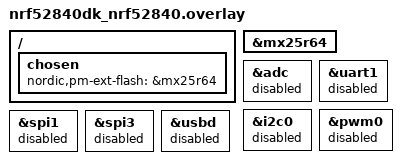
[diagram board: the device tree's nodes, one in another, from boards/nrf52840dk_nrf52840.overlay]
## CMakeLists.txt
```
#
# Copyright (c) 2021 Nordic Semiconductor ASA
#
# SPDX-License-Identifier: LicenseRef-Nordic-5-Clause
#

cmake_minimum_required(VERSION 3.20.0)

include(${CMAKE_CURRENT_LIST_DIR}/../../cmake/find_zephyr.cmake)

project(matter-light-switch)

# NORDIC SDK APP START

# Include all source files that are located in the Matter common directory.
include(${ZEPHYR_NCS_MATTER_MODULE_DIR}/cmake/sample.cmake)

ncs_get_zap_parent_dir(ZAP_PARENT_DIR)

target_include_directories(app PRIVATE
  src
  ${ZAP_PARENT_DIR}
)

target_compile_options(app PRIVATE -Wno-deprecated-declarations)

target_sources(app PRIVATE
  src/app_task.cpp
  src/light_switch.cpp
  src/main.cpp
  src/shell_commands.cpp
  ${ZEPHYR_NCS_MATTER_MODULE_DIR}/subsys/binding/binding_handler.cpp
)

ncs_configure_data_model()
# NORDIC SDK APP END
```

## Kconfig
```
#
# Copyright (c) 2022 Nordic Semiconductor
#
# SPDX-License-Identifier: LicenseRef-Nordic-5-Clause
#
mainmenu "Matter nRF Connect Light Switch Example Application"

config STATE_LEDS
	bool "Use LEDs to indicate the device state"
	default y
	help
	  Use LEDs to render the current state of the device such as the progress of commissioning of
	  the device into a network or the factory reset initiation. Note that setting this option to
	  'n' does not disable the LED indicating the state of the simulated bolt.

# Sample configuration used for Thread networking
if OPENTHREAD

choice OPENTHREAD_NORDIC_LIBRARY_CONFIGURATION
	default OPENTHREAD_NORDIC_LIBRARY_MTD
endchoice

choice OPENTHREAD_DEVICE_TYPE
	default OPENTHREAD_MTD
endchoice

choice OPENTHREAD_IMPLEMENTATION
	default OPENTHREAD_SOURCES
endchoice

config CHIP_ENABLE_ICD_SUPPORT
	default y

# Reduce Thread TX output power to 0 dBm for SED device
config OPENTHREAD_DEFAULT_TX_POWER
	default 0

endif # OPENTHREAD

if SHIELD_NRF7002EB2

config CHIP_WIFI
	default y

config NRF_WIFI_LOW_POWER
	default y

endif # SHIELD_NRF7002EB2

# Enable Read Client functionality for all build configurations.
config CHIP_ENABLE_READ_CLIENT
	default y

source "$(ZEPHYR_CONNECTEDHOMEIP_MODULE_DIR)/config/nrfconnect/chip-module/Kconfig.features"
source "$(ZEPHYR_CONNECTEDHOMEIP_MODULE_DIR)/config/nrfconnect/chip-module/Kconfig.defaults"
source "Kconfig.zephyr"
```

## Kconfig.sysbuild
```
#
# Copyright (c) 2023 Nordic Semiconductor ASA
#
# SPDX-License-Identifier: LicenseRef-Nordic-5-Clause
#

config MATTER_ADD_ON
	default y

#### Radio core selection
config NRF_DEFAULT_IPC_RADIO
	default y

# Enable IEEE802.15.4 serialization to network core
# This config automatically pulls in the `overlay-802154.conf` in the ipc_radio image
config NETCORE_IPC_RADIO_IEEE802154
	default y if SOC_SERIES_NRF53 && !WIFI_NRF70

# Enable Bluetooth serialization to network core
# This config automatically pulls in the `overlay-bt_hci_ipc.conf` in the ipc_radio image
config NETCORE_IPC_RADIO_BT_HCI_IPC
	default y if SOC_SERIES_NRF53

#### Matter OTA
config MATTER_ADD_ON_OTA
	default n if BOARD_NRF7120DK_NRF7120_CPUAPP

#### Bootloader
choice BOOTLOADER
	default BOOTLOADER_MCUBOOT if !BOARD_NRF21540DK && !BOARD_NRF7120DK_NRF7120_CPUAPP
endchoice

if BOOTLOADER_MCUBOOT

#### DFU multi-image support
config DFU_MULTI_IMAGE_PACKAGE_BUILD
	default y

config DFU_MULTI_IMAGE_PACKAGE_APP
	default y

#### DFU network core configuration
if SOC_SERIES_NRF53

choice MCUBOOT_MODE
	default MCUBOOT_MODE_OVERWRITE_ONLY
endchoice

choice BOOT_SIGNATURE_TYPE
	default BOOT_SIGNATURE_TYPE_RSA
endchoice

config SECURE_BOOT_NETCORE
	default y

config NETCORE_APP_UPDATE
	default y

config DFU_MULTI_IMAGE_PACKAGE_NET
	default y

endif # SOC_SERIES_NRF53
endif # BOOTLOADER_MCUBOOT

#### Enable generating factory data
config MATTER_ADD_ON_FACTORY_DATA_GENERATE
	default y if !BOARD_NRF21540DK

source "share/sysbuild/Kconfig"
```

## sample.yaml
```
sample:
  description: Matter Light Switch example
  name: Matter Light Switch
common:
  tags:
    - sysbuild
    - ci_samples_matter
tests:
  sample.matter.light_switch.debug:
    sysbuild: true
    build_only: true
    integration_platforms:
      - nrf5340dk/nrf5340/cpuapp
      - nrf54lm20dk/nrf54lm20b/cpuapp
      - nrf54lm20dk/nrf54lm20a/cpuapp
    platform_allow:
      - nrf5340dk/nrf5340/cpuapp
      - nrf54l15dk/nrf54l15/cpuapp
      - nrf54lm20dk/nrf54lm20b/cpuapp
      - nrf54lm20dk/nrf54lm20a/cpuapp
  sample.matter.light_switch.nrf7002eb2.debug:
    sysbuild: true
    build_only: true
    extra_args:
      - light_switch_SHIELD=nrf7002eb2
      - SB_CONFIG_WIFI_NRF70=y
    integration_platforms:
      - nrf54lm20dk/nrf54lm20b/cpuapp
      - nrf54lm20dk/nrf54lm20a/cpuapp
    platform_allow:
      - nrf54lm20dk/nrf54lm20b/cpuapp
      - nrf54lm20dk/nrf54lm20a/cpuapp
  sample.matter.light_switch.nrf7120.debug:
    sysbuild: true
    build_only: true
    extra_args:
      - CONFIG_CHIP_WIFI=y
      - CONFIG_WIFI_NRF71_PATCH=y
      - EXTRA_DTC_OVERLAY_FILE=${ZEPHYR_NRFXLIB_MODULE_DIR}/nrf71_wifi/bins/0.1.0/nrf7120_wifi_patch.dtsi
    integration_platforms:
      - nrf7120dk/nrf7120/cpuapp
    platform_allow:
      - nrf7120dk/nrf7120/cpuapp
  sample.matter.light_switch.release:
    sysbuild: true
    build_only: true
    extra_args:
      - FILE_SUFFIX=release
    integration_platforms:
      - nrf54lm20dk/nrf54lm20b/cpuapp
      - nrf54lm20dk/nrf54lm20a/cpuapp
    platform_allow:
      - nrf5340dk/nrf5340/cpuapp
      - nrf54l15dk/nrf54l15/cpuapp
      - nrf54lm20dk/nrf54lm20b/cpuapp
      - nrf54lm20dk/nrf54lm20a/cpuapp
  sample.matter.light_switch.nrf7002eb2.release:
    sysbuild: true
    build_only: true
    extra_args:
      - FILE_SUFFIX=release
      - light_switch_SHIELD=nrf7002eb2
      - SB_CONFIG_WIFI_NRF70=y
    integration_platforms:
      - nrf54lm20dk/nrf54lm20b/cpuapp
      - nrf54lm20dk/nrf54lm20a/cpuapp
    platform_allow:
      - nrf54lm20dk/nrf54lm20b/cpuapp
      - nrf54lm20dk/nrf54lm20a/cpuapp
  sample.matter.light_switch.nrf7120.release:
    sysbuild: true
    build_only: true
    extra_args:
      - FILE_SUFFIX=release
      - CONFIG_CHIP_WIFI=y
      - CONFIG_WIFI_NRF71_PATCH=y
      - EXTRA_DTC_OVERLAY_FILE=${ZEPHYR_NRFXLIB_MODULE_DIR}/nrf71_wifi/bins/0.1.0/nrf7120_wifi_patch.dtsi
    integration_platforms:
      - nrf7120dk/nrf7120/cpuapp
    platform_allow:
      - nrf7120dk/nrf7120/cpuapp
  sample.matter.light_switch.lit_icd:
    sysbuild: true
    build_only: true
    extra_args:
      - EXTRA_CONF_FILE=icd_lit.conf
    integration_platforms:
      - nrf5340dk/nrf5340/cpuapp
      - nrf54l15dk/nrf54l15/cpuapp
    platform_allow:
      - nrf5340dk/nrf5340/cpuapp
      - nrf54l15dk/nrf54l15/cpuapp
  sample.matter.light_switch.tfm:
    sysbuild: true
    build_only: true
    extra_args:
      - FILE_SUFFIX=tfm
    integration_platforms:
      - nrf54l15dk/nrf54l15/cpuapp/ns
    platform_allow:
      - nrf54l15dk/nrf54l15/cpuapp/ns
```

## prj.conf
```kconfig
#
# Copyright (c) 2021 Nordic Semiconductor ASA
#
# SPDX-License-Identifier: LicenseRef-Nordic-5-Clause
#

# Enable CHIP
CONFIG_CHIP=y
CONFIG_CHIP_PROJECT_CONFIG="src/chip_project_config.h"
CONFIG_CHIP_DEVICE_PRODUCT_NAME="Matter Light Switch"

# Configure ZAP file name
CONFIG_MATTER_ZAP_FILE_PATH="${APPLICATION_CONFIG_DIR}/src/default_zap/light_switch.zap"

# 32772 == 0x8004 (example light-switch-app)
CONFIG_CHIP_DEVICE_PRODUCT_ID=32772
CONFIG_STD_CPP17=y

# Enable Matter pairing automatically on application start.
CONFIG_CHIP_ENABLE_PAIRING_AUTOSTART=y

# Enable Matter extended announcement and increase duration to 1 hour.
CONFIG_CHIP_BLE_EXT_ADVERTISING=y
CONFIG_CHIP_BLE_ADVERTISING_DURATION=60

# Add support for LEDs and buttons on Nordic development kits
CONFIG_DK_LIBRARY=y

# Bluetooth Low Energy configuration
CONFIG_BT_DEVICE_NAME="MatterSwitch"

# Suspend devices when the CPU goes into sleep
CONFIG_PM_DEVICE=y

# Other settings
CONFIG_THREAD_NAME=y
CONFIG_MPU_STACK_GUARD=y
CONFIG_RESET_ON_FATAL_ERROR=n
CONFIG_CHIP_LIB_SHELL=y
CONFIG_MATTER_TEST_SHELL=y

# Reduce application size
CONFIG_USE_SEGGER_RTT=n

# Enable Factory Data feature
CONFIG_CHIP_FACTORY_DATA=y
CONFIG_CHIP_FACTORY_DATA_BUILD=y
```

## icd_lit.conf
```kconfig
#
# Copyright (c) 2026 Nordic Semiconductor ASA
#
# SPDX-License-Identifier: LicenseRef-Nordic-5-Clause
#

# Enable LIT ICD configuration
CONFIG_CHIP_ICD_LIT_SUPPORT=y
CONFIG_CHIP_ICD_SIT_SLOW_POLL_LIMIT=5000
CONFIG_CHIP_ICD_REPORT_ON_ACTIVE_MODE=y

# Configure ZAP file name
CONFIG_MATTER_ZAP_FILE_PATH="${APPLICATION_CONFIG_DIR}/src/lit_icd_zap/light_switch.zap"
```

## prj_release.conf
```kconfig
#
# Copyright (c) 2021 Nordic Semiconductor ASA
#
# SPDX-License-Identifier: LicenseRef-Nordic-5-Clause
#

# Enable CHIP
CONFIG_CHIP=y
CONFIG_CHIP_PROJECT_CONFIG="src/chip_project_config.h"
CONFIG_CHIP_DEVICE_PRODUCT_NAME="Matter Light Switch"

# Configure ZAP file name
CONFIG_MATTER_ZAP_FILE_PATH="${APPLICATION_CONFIG_DIR}/src/default_zap/light_switch.zap"

# 32772 == 0x8004 (example light-switch-app)
CONFIG_CHIP_DEVICE_PRODUCT_ID=32772
CONFIG_STD_CPP17=y

# Enable Matter pairing automatically on application start.
CONFIG_CHIP_ENABLE_PAIRING_AUTOSTART=y

# Enable Matter extended announcement and increase duration to 1 hour.
CONFIG_CHIP_BLE_EXT_ADVERTISING=y
CONFIG_CHIP_BLE_ADVERTISING_DURATION=60

# Add support for LEDs and buttons on Nordic development kits
CONFIG_DK_LIBRARY=y

# Try to disable unused RAM blocks to reduce power consumption
CONFIG_RAM_POWER_DOWN_LIBRARY=y

# Bluetooth Low Energy configuration
CONFIG_BT_DEVICE_NAME="MatterSwitch"

# Suspend devices when the CPU goes into sleep
CONFIG_PM_DEVICE=y

# Enable system reset on fatal error
CONFIG_RESET_ON_FATAL_ERROR=y

# Disable all debug features
CONFIG_USE_SEGGER_RTT=n
CONFIG_SHELL=n
CONFIG_OPENTHREAD_SHELL=n
CONFIG_CONSOLE=n
CONFIG_UART_CONSOLE=n
CONFIG_SERIAL=n
CONFIG_LOG=n
CONFIG_LOG_MODE_MINIMAL=n
CONFIG_ASSERT_VERBOSE=n
CONFIG_ASSERT_NO_FILE_INFO=y
CONFIG_PRINTK=n
CONFIG_PRINTK_SYNC=n
CONFIG_THREAD_NAME=n
CONFIG_BOOT_BANNER=n

# Enable Factory Data feature
CONFIG_CHIP_FACTORY_DATA=y
CONFIG_CHIP_FACTORY_DATA_BUILD=y

# Enable Watchdog
CONFIG_MATTER_WATCHDOG=y

# Enable LTO to decrease the flash usage.
CONFIG_LTO=y
CONFIG_ISR_TABLES_LOCAL_DECLARATION=y
```

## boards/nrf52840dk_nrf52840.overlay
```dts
/*
 * Copyright (c) 2021 Nordic Semiconductor ASA
 *
 * SPDX-License-Identifier: LicenseRef-Nordic-5-Clause
 */

#include <nrf52840_partitions.dtsi>

/ {
	chosen {
		nordic,pm-ext-flash = &mx25r64;
	};
};

&mx25r64 {
	status = "okay";
};

/* Disable unused peripherals to reduce power consumption */
&adc {
	status = "disabled";
};

&uart1 {
	status = "disabled";
};

&i2c0 {
	status = "disabled";
};

&pwm0 {
	status = "disabled";
};

&spi1 {
	status = "disabled";
};

&spi3 {
	status = "disabled";
};

&usbd {
	status = "disabled";
};
```

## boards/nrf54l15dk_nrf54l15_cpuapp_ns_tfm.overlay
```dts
/*
 * Copyright (c) 2026 Nordic Semiconductor ASA
 *
 * SPDX-License-Identifier: LicenseRef-Nordic-5-Clause
 */

#include <nrf54l15_cpuapp_tfm_application_partitions.dtsi>

/ {
	aliases {
		/* Use watchdog wdt31 as the application watchdog */
		watchdog0 = &wdt31;
	};

	chosen {
		nordic,pm-ext-flash = &mx25r64;
	};
};

&mx25r64 {
	status = "okay";
};

&wdt31 {
	status = "okay";
};

/* Change IRQ ids to handle button interrupts.
 * The default values for nRF54L15 are 219 and 269,
 * but with TF-M they are reserved for the secure domain
 * (218 and 268 are reserved for the non-secure domain).
 */
&gpiote20 {
	interrupts = <218 NRF_DEFAULT_IRQ_PRIORITY>;
};

&gpiote30 {
	interrupts = <268 NRF_DEFAULT_IRQ_PRIORITY>;
};
```

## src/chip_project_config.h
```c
/*
 * Copyright (c) 2022 Nordic Semiconductor ASA
 *
 * SPDX-License-Identifier: LicenseRef-Nordic-5-Clause
 */

#pragma once

#include "../../../subsys/app/chip_project_config_native_sim.h"

#define CHIP_CONFIG_CONTROLLER_MAX_ACTIVE_DEVICES 2
```

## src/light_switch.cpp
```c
/*
 * Copyright (c) 2022 Nordic Semiconductor ASA
 *
 * SPDX-License-Identifier: LicenseRef-Nordic-5-Clause
 */

#include "light_switch.h"
#include "binding/binding_handler.h"

#ifdef CONFIG_CHIP_LIB_SHELL
#include "shell_commands.h"
#endif

#include <app/clusters/bindings/binding-table.h>
#include <app/server/Server.h>
#include <controller/InvokeInteraction.h>
#include <platform/CHIPDeviceLayer.h>
#include <zephyr/logging/log.h>

using namespace chip;
using namespace chip::app;
using namespace chip::app::Clusters;

LOG_MODULE_DECLARE(app, CONFIG_CHIP_APP_LOG_LEVEL);

void LightSwitch::Init(chip::EndpointId lightSwitchEndpoint)
{
	Nrf::Matter::BindingHandler::Init();
#ifdef CONFIG_CHIP_LIB_SHELL
	SwitchCommands::RegisterSwitchCommands();
#endif
	mLightSwitchEndpoint = lightSwitchEndpoint;
}

void LightSwitch::InitiateActionSwitch(Action action)
{
	Nrf::Matter::BindingHandler::BindingData *data = Platform::New<Nrf::Matter::BindingHandler::BindingData>();
	if (data) {
		data->EndpointId = mLightSwitchEndpoint;
		data->ClusterId = Clusters::OnOff::Id;
		data->InvokeCommandFunc = SwitchChangedHandler;
		switch (action) {
		case Action::Toggle:
			data->CommandId = Clusters::OnOff::Commands::Toggle::Id;
			break;
		case Action::On:
			data->CommandId = Clusters::OnOff::Commands::On::Id;
			break;
		case Action::Off:
			data->CommandId = Clusters::OnOff::Commands::Off::Id;
			break;
		default:
			Platform::Delete(data);
			return;
		}
		Nrf::Matter::BindingHandler::RunBoundClusterAction(data);
	}
}

void LightSwitch::DimmerChangeBrightness()
{
	static uint16_t sBrightness;
	Nrf::Matter::BindingHandler::BindingData *data = Platform::New<Nrf::Matter::BindingHandler::BindingData>();
	if (data) {
		data->EndpointId = mLightSwitchEndpoint;
		data->CommandId = Clusters::LevelControl::Commands::MoveToLevel::Id;
		data->ClusterId = Clusters::LevelControl::Id;
		data->InvokeCommandFunc = SwitchChangedHandler;
		/* add to brightness 3 to approximate 1% step of brightness after each call dimmer change. */
		sBrightness += kOnePercentBrightnessApproximation;
		if (sBrightness > kMaximumBrightness) {
			sBrightness = 0;
		}
		data->Value = (uint8_t)sBrightness;
		Nrf::Matter::BindingHandler::RunBoundClusterAction(data);
	}
}

void LightSwitch::SwitchChangedHandler(const Binding::TableEntry &binding, OperationalDeviceProxy *deviceProxy,
				       Nrf::Matter::BindingHandler::BindingData &bindingData)
{
	if (binding.type == Binding::MATTER_MULTICAST_BINDING) {
		switch (bindingData.ClusterId) {
		case Clusters::OnOff::Id:
			OnOffProcessCommand(bindingData.CommandId, binding, nullptr, bindingData);
			break;
		case Clusters::LevelControl::Id:
			LevelControlProcessCommand(bindingData.CommandId, binding, nullptr, bindingData);
			break;
		default:
			ChipLogError(NotSpecified, "Invalid binding group command data");
			break;
		}
	} else if (binding.type == Binding::MATTER_UNICAST_BINDING) {
		switch (bindingData.ClusterId) {
		case Clusters::OnOff::Id:
			OnOffProcessCommand(bindingData.CommandId, binding, deviceProxy, bindingData);
			break;
		case Clusters::LevelControl::Id:
			LevelControlProcessCommand(bindingData.CommandId, binding, deviceProxy, bindingData);
			break;
		default:
			ChipLogError(NotSpecified, "Invalid binding unicast command data");
			break;
		}
	}
}

void LightSwitch::OnOffProcessCommand(CommandId commandId, const Binding::TableEntry &binding,
				      OperationalDeviceProxy *device,
				      Nrf::Matter::BindingHandler::BindingData &bindingData)
{
	CHIP_ERROR ret = CHIP_NO_ERROR;

	Nrf::Matter::BindingHandler::BindingData *dataPointer =
		device ? Platform::New<Nrf::Matter::BindingHandler::BindingData>(bindingData) : nullptr;

	auto onSuccess = [dataPointer](const ConcreteCommandPath &commandPath, const StatusIB &status,
				       const auto &dataResponse) {
		Nrf::Matter::BindingHandler::OnInvokeCommandSucces(dataPointer);
	};

	auto onFailure = [dataPointer](CHIP_ERROR aError) mutable {
		Nrf::Matter::BindingHandler::OnInvokeCommandFailure(dataPointer, aError);
	};

	if (device) {
		/* We are validating connection is ready once here instead of multiple times in each case
		 * statement below. */
		VerifyOrDie(device->ConnectionReady());
	}

	switch (commandId) {
	case Clusters::OnOff::Commands::Toggle::Id:
		Clusters::OnOff::Commands::Toggle::Type toggleCommand;
		if (device) {
			ret = Controller::InvokeCommandRequest(device->GetExchangeManager(),
							       device->GetSecureSession().Value(), binding.remote,
							       toggleCommand, onSuccess, onFailure);
		} else {
			Messaging::ExchangeManager &exchangeMgr = Server::GetInstance().GetExchangeManager();
			ret = Controller::InvokeGroupCommandRequest(&exchangeMgr, binding.fabricIndex, binding.groupId,
								    toggleCommand);
		}
		break;

	case Clusters::OnOff::Commands::On::Id:
		Clusters::OnOff::Commands::On::Type onCommand;
		if (device) {
			ret = Controller::InvokeCommandRequest(device->GetExchangeManager(),
							       device->GetSecureSession().Value(), binding.remote,
							       onCommand, onSuccess, onFailure);
		} else {
			Messaging::ExchangeManager &exchangeMgr = Server::GetInstance().GetExchangeManager();
			ret = Controller::InvokeGroupCommandRequest(&exchangeMgr, binding.fabricIndex, binding.groupId,
								    onCommand);
		}
		break;

	case Clusters::OnOff::Commands::Off::Id:
		Clusters::OnOff::Commands::Off::Type offCommand;
		if (device) {
			ret = Controller::InvokeCommandRequest(device->GetExchangeManager(),
							       device->GetSecureSession().Value(), binding.remote,
							       offCommand, onSuccess, onFailure);
		} else {
			Messaging::ExchangeManager &exchangeMgr = Server::GetInstance().GetExchangeManager();
			ret = Controller::InvokeGroupCommandRequest(&exchangeMgr, binding.fabricIndex, binding.groupId,
								    offCommand);
		}
		break;
	default:
		LOG_DBG("Invalid binding command data - commandId is not supported");
		ret = CHIP_ERROR_INVALID_ARGUMENT;
		break;
	}
	if (CHIP_NO_ERROR != ret) {
		LOG_ERR("Invoke OnOff Command Request ERROR: %s", ErrorStr(ret));
	}

	if (dataPointer && CHIP_NO_ERROR != ret) {
		Platform::Delete<Nrf::Matter::BindingHandler::BindingData>(dataPointer);
	}
}

void LightSwitch::LevelControlProcessCommand(CommandId commandId, const Binding::TableEntry &binding,
					     OperationalDeviceProxy *device,
					     Nrf::Matter::BindingHandler::BindingData &bindingData)
{
	Nrf::Matter::BindingHandler::BindingData *dataPointer =
		device ? Platform::New<Nrf::Matter::BindingHandler::BindingData>(bindingData) : nullptr;

	auto onSuccess = [dataPointer](const ConcreteCommandPath &commandPath, const StatusIB &status,
				       const auto &dataResponse) {
		Nrf::Matter::BindingHandler::OnInvokeCommandSucces(dataPointer);
	};

	auto onFailure = [dataPointer](CHIP_ERROR aError) mutable {
		Nrf::Matter::BindingHandler::OnInvokeCommandFailure(dataPointer, aError);
	};

	CHIP_ERROR ret = CHIP_NO_ERROR;

	if (device) {
		/* We are validating connection is ready once here instead of multiple times in each case
		 * statement below.
		 */
		VerifyOrDie(device->ConnectionReady());
	}

	switch (commandId) {
	case Clusters::LevelControl::Commands::MoveToLevel::Id: {
		Clusters::LevelControl::Commands::MoveToLevel::Type moveToLevelCommand;
		moveToLevelCommand.level = bindingData.Value;
		if (device) {
			ret = Controller::InvokeCommandRequest(device->GetExchangeManager(),
							       device->GetSecureSession().Value(), binding.remote,
							       moveToLevelCommand, onSuccess, onFailure);
		} else {
			Messaging::ExchangeManager &exchangeMgr = Server::GetInstance().GetExchangeManager();
			ret = Controller::InvokeGroupCommandRequest(&exchangeMgr, binding.fabricIndex, binding.groupId,
								    moveToLevelCommand);
		}
	} break;
	default:
		LOG_DBG("Invalid binding command data - commandId is not supported");
		ret = CHIP_ERROR_INVALID_ARGUMENT;
		break;
	}
	if (CHIP_NO_ERROR != ret) {
		LOG_ERR("Invoke Group Command Request ERROR: %s", ErrorStr(ret));
	}

	if (dataPointer && CHIP_NO_ERROR != ret) {
		Platform::Delete<Nrf::Matter::BindingHandler::BindingData>(dataPointer);
	}
}
```
